# M4G7 register map
File version: 0.1
Registers are 32-bit, read-write, reset 0x0 unless marked. A register's access mark holds for its fields unless they carry their own. Offsets are from the block's base; [hi:lo] are bit positions; {n}, {i} and the like mark numbered series.

## PT — Port T
Base 0x400E0F00
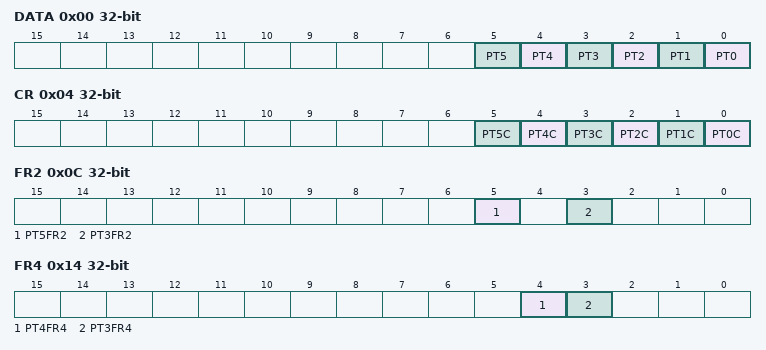
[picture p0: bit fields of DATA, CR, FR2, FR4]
0x00 DATA — Port T Data Register
  [n] PT{n} (n=0..5)
0x04 CR — Port T Output Control Register
  [n] PT{n}C (n=0..5)
0x08 FR1 — Port T Function Register 1
  [3] PT3FR1
0x0C FR2 — Port T Function Register 2
  [5] PT5FR2, [3] PT3FR2
0x10 FR3 — Port T Function Register 3
  [3] PT3FR3
0x14 FR4 — Port T Function Register 4
  [4] PT4FR4, [3] PT3FR4
0x1C FR6 — Port T Function Register 6
  [3] PT3FR6
0x20 FR7 — Port T Function Register 7
  [2] PT2FR7
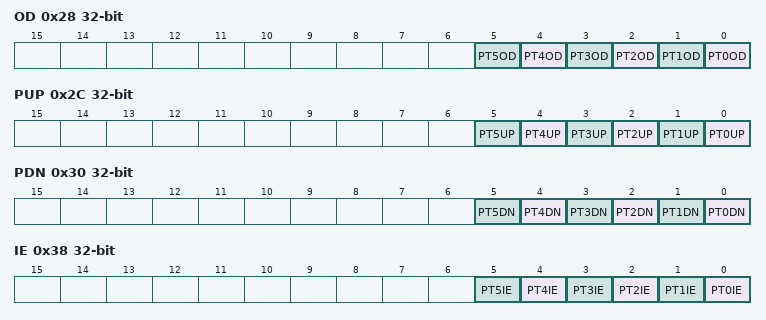
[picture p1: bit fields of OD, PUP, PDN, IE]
0x28 OD — Port T Open Drain Control Register
  [n] PT{n}OD (n=0..5)
0x2C PUP — Port T Pull-up Control Register
  [n] PT{n}UP (n=0..5)
0x30 PDN — Port T Pull-down Control Register
  [n] PT{n}DN (n=0..5)
0x38 IE — Port T Input Control Register
  [n] PT{n}IE (n=0..5)

## PV — Port V
Base 0x400E1100
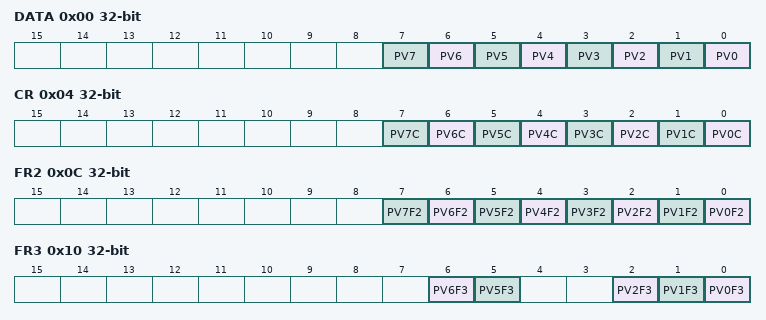
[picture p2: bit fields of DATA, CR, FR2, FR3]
0x00 DATA — Port V Data Register
  [n] PV{n} (n=0..7)
0x04 CR — Port V OutPut Control Register
  [n] PV{n}C (n=0..7)
0x0C FR2 — Port V Function Register 2
  [n] PV{n}F2 (n=0..7)
0x10 FR3 — Port V Function Register 3
  [6] PV6F3, [5] PV5F3, [2] PV2F3, [1] PV1F3, [0] PV0F3
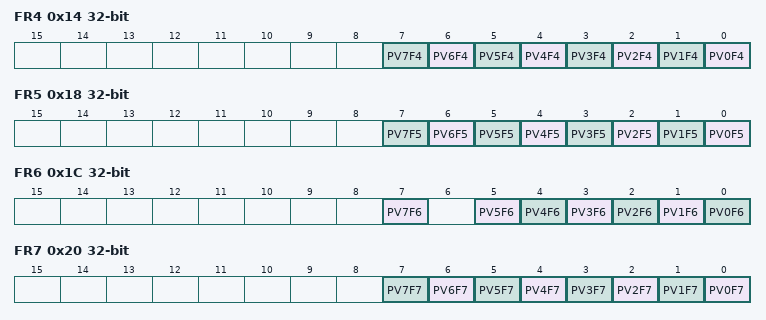
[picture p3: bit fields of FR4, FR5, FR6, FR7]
0x14 FR4 — Port V Function Register 4
  [n] PV{n}F4 (n=0..7)
0x18 FR5 — Port V Function Register 5
  [n] PV{n}F5 (n=0..7)
0x1C FR6 — Port V Function Register 6
  [7] PV7F6, [n] PV{n}F6 (n=0..5)
0x20 FR7 — Port V Function Register 7
  [n] PV{n}F7 (n=0..7)
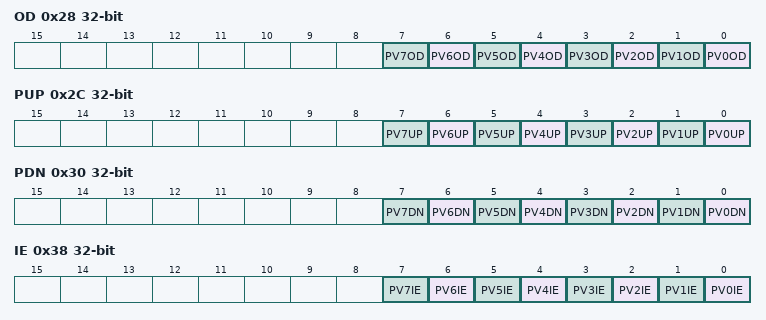
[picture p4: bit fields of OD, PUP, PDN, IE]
0x28 OD — Port V Open Drain Control Register
  [n] PV{n}OD (n=0..7)
0x2C PUP — Port V Pull-up Control Register
  [n] PV{n}UP (n=0..7)
0x30 PDN — Port V Pull-down Control Register
  [n] PV{n}DN (n=0..7)
0x38 IE — Port V InPut Control Register
  [n] PV{n}IE (n=0..7)

## PY — Port Y
Base 0x400E1300
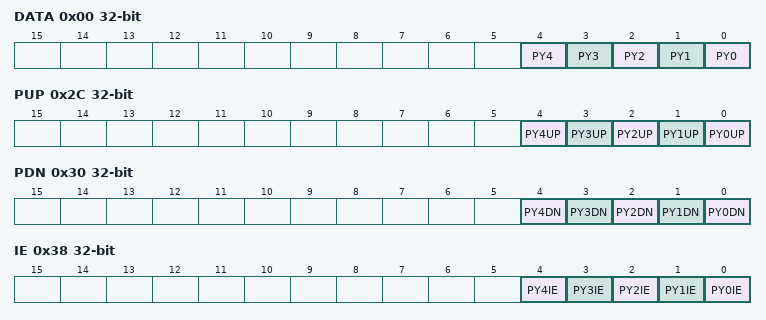
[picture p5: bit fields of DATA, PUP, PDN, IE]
0x00 DATA — Port Y Data Register
  [n] PY{n} (n=0..4)
0x04 CR — Port Y OutPut Control Register
  [4] PY4C
0x08 FR1 — Port Y Function Register 1
  [4] PY4F1
0x14 FR4 — Port Y Function Register 4
  [4] PY4F4
0x28 OD — Port Y Open Drain Control Register
  [4] PY4OD
0x2C PUP — Port Y Pull-up Control Register
  [n] PY{n}UP (n=0..4)
0x30 PDN — Port Y Pull-down Control Register
  [n] PY{n}DN (n=0..4)
0x38 IE — Port Y InPut Control Register
  [n] PY{n}IE (n=0..4)

## TRMOSC — Internal High-speed Oscillation Adjustment
Base 0x400E3100
0x00 PRO — Protection Register
  [7:0] PROTECT
0x04 EN — Enable Register
  [0] TRIMEN
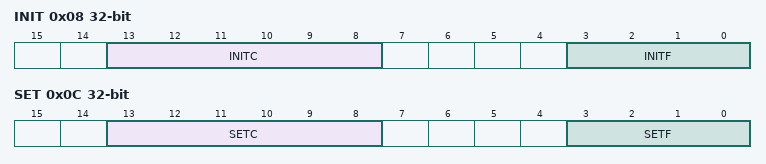
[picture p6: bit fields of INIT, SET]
0x08 INIT ro (reset mask 0xFFFFC0F0) — Initial Trimming Level Monitor Register
  [13:8] INITC, [3:0] INITF
0x0C SET — Trimming Level Setting Register
  [13:8] SETC, [3:0] SETF

## OFD — Oscillation Frequency Detector (OFD)
Base 0x400E4000
0x00 CR1 reset 0x6 — OFD Control Register 1
  [7:0] OFDWEN
0x04 CR2 — OFD Control Register 2
  [7:0] OFDEN
0x08 MN0 — OFD Lower Detection Frequency Setting Register0
  [11:0] OFDMN0
0x0C MN1 — OFD Lower Detection Frequency Setting Register1
  [11:0] OFDMN1
0x10 MX0 — OFD Higher Detection Frequency Setting Register0
  [11:0] OFDMX0
0x14 MX1 — OFD Higher Detection Frequency Setting Register1
  [11:0] OFDMX1
0x18 RST reset 0x1 — OFD Reset Enable Control Register
  [0] OFDRSTEN
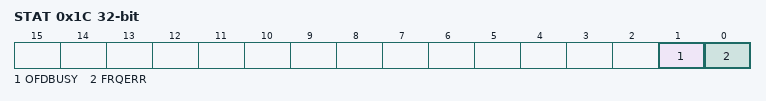
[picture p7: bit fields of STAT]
0x1C STAT ro — OFD Status Register
  [1] OFDBUSY, [0] FRQERR
0x20 MON reset 0x1 — OFD External high frequency oscillaion clock monitor register
  [0] OFDMON

## RTC — Real Time Clock (RTC)
Base 0x400E4800
0x00 SECR 8-bit (reset mask 0x80) — RTC Sec setting register
  [6:0] SE
0x01 MINR 8-bit (reset mask 0x80) — RTC Min settging register
  [6:0] MI
0x02 HOURR 8-bit (reset mask 0xC0) — RTC Hour setting register
  [5:0] HO
0x04 DAYR 8-bit (reset mask 0xF8) — RTC Day setting register
  [2:0] WE
0x05 DATER 8-bit (reset mask 0xC0) — RTC Date setting register
  [5:0] DA
0x06 MONTHR_A 8-bit (reset mask 0xE0) — RTC Month settging register PAGE0
  [4:0] MO
0x06 MONTHR_B 8-bit (reset mask 0xFE) (RTC_MONTHR view) — RTC Month settging register PAGE0
  [0] MO0
0x07 YEARR_A 8-bit reset not defined — RTC Year setting register PAGE0
  [7:0] YE
0x07 YEARR_B 8-bit (reset mask 0xFC) (RTC_YEARR view) — RTC Leap year register PAGE1
  [1:0] LEAP
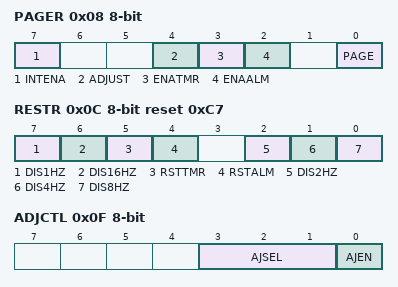
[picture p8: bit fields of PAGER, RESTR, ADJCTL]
0x08 PAGER 8-bit (reset mask 0xF3) — RTC Page register
  [7] INTENA, [4] ADJUST, [3] ENATMR, [2] ENAALM, [0] PAGE
0x0C RESTR 8-bit reset 0xC7 — RTC Reset register
  [7] DIS1HZ, [6] DIS16HZ, [5] RSTTMR, [4] RSTALM, [2] DIS2HZ, [1] DIS4HZ, [0] DIS8HZ
0x0E PROTECT 8-bit reset 0xC1 — RTC clock adjust control register
0x0F ADJCTL 8-bit — RTC protect register
  [3:1] AJSEL, [0] AJEN
0x10 ADJDAT 8-bit reset not defined — RTC clock adjust data register
0x11 ADJSIGN 8-bit (reset mask 0xFE)
  [0] ADJSIGN
